# STM32G431C6T6 register map
File version: 1.0
Registers are 32-bit, access not given, reset 0x0 unless marked. A register's access mark holds for its fields unless they carry their own. Offsets are from the block's base; [hi:lo] are bit positions; {n}, {i} and the like mark numbered series; 'fields as' and 'values as' point back to an identical list.

## HRTIM
Base 0x40016800
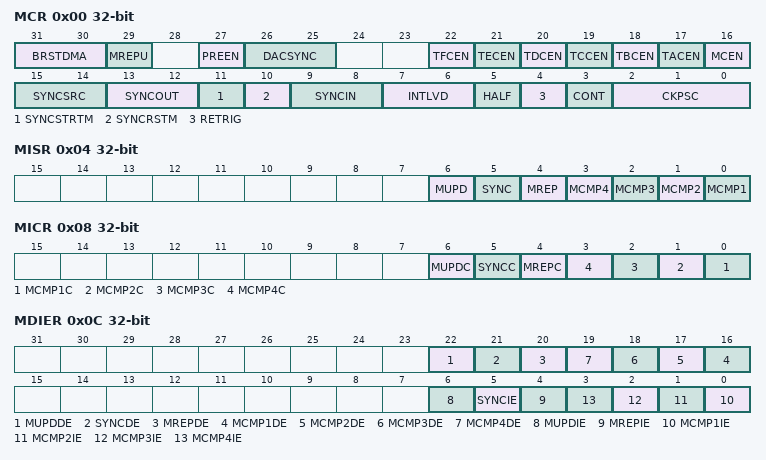
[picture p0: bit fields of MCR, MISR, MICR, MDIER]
0x00 MCR
  [31:30] BRSTDMA, [29] MREPU, [27] PREEN, [26:25] DACSYNC, [22] TFCEN, [21] TECEN, [20] TDCEN, [19] TCCEN, [18] TBCEN, [17] TACEN, [16] MCEN, [15:14] SYNCSRC, [13:12] SYNCOUT, [11] SYNCSTRTM, [10] SYNCRSTM, [9:8] SYNCIN, [7:6] INTLVD, [5] HALF, [4] RETRIG, [3] CONT, [2:0] CKPSC
0x04 MISR
  [6] MUPD, [5] SYNC, [4] MREP, [n-1] MCMP{n} (n=1..4)
0x08 MICR
  [6] MUPDC, [5] SYNCC, [4] MREPC, [n-1] MCMP{n}C (n=1..4)
0x0C MDIER
  [22] MUPDDE, [21] SYNCDE, [20] MREPDE, [n+15] MCMP{n}DE (n=1..4), [6] MUPDIE, [5] SYNCIE, [4] MREPIE, [n-1] MCMP{n}IE (n=1..4)
0x10 MCNTR
  [15:0] MCNT
0x14 MPER
  [15:0] MPER
0x18 MREP
  [7:0] MREP
0x1C MCMP1R
  [15:0] MCMP1
{0x1C+4i} MCMP{i}R (i=2..4)
  [15:0] MCMP{i}
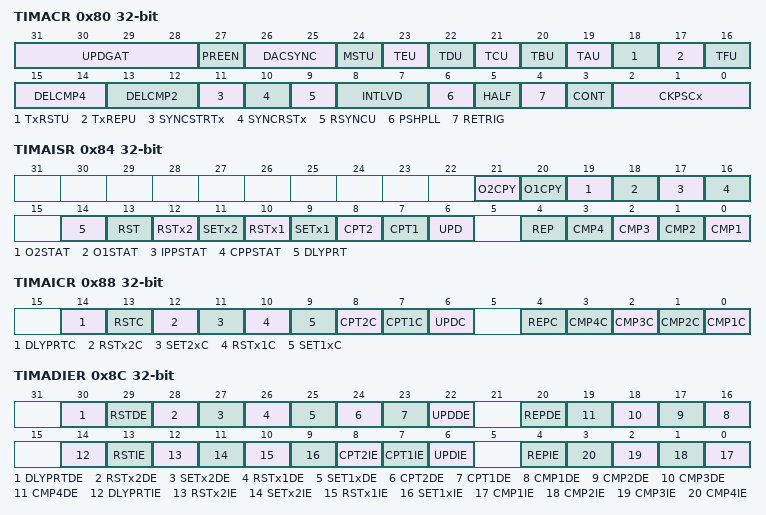
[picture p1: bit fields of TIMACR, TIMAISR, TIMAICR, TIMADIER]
0x80 TIMACR
  [31:28] UPDGAT, [27] PREEN, [26:25] DACSYNC, [24] MSTU, [23] TEU, [22] TDU, [21] TCU, [20] TBU, [19] TAU, [18] TxRSTU, [17] TxREPU, [16] TFU, [15:14] DELCMP4, [13:12] DELCMP2, [11] SYNCSTRTx, [10] SYNCRSTx, [9] RSYNCU, [8:7] INTLVD, [6] PSHPLL, [5] HALF, [4] RETRIG, [3] CONT, [2:0] CKPSCx
0x84 TIMAISR
  [21] O2CPY, [20] O1CPY, [19] O2STAT, [18] O1STAT, [17] IPPSTAT, [16] CPPSTAT, [14] DLYPRT, [13] RST, [12] RSTx2, [11] SETx2, [10] RSTx1, [9] SETx1, [8] CPT2, [7] CPT1, [6] UPD, [4] REP, [n-1] CMP{n} (n=1..4)
0x88 TIMAICR
  [14] DLYPRTC, [13] RSTC, [12] RSTx2C, [11] SET2xC, [10] RSTx1C, [9] SET1xC, [8] CPT2C, [7] CPT1C, [6] UPDC, [4] REPC, [n-1] CMP{n}C (n=1..4)
0x8C TIMADIER
  [30] DLYPRTDE, [29] RSTDE, [28] RSTx2DE, [27] SETx2DE, [26] RSTx1DE, [25] SET1xDE, [24] CPT2DE, [23] CPT1DE, [22] UPDDE, [20] REPDE, [n+15] CMP{n}DE (n=1..4), [14] DLYPRTIE, [13] RSTIE, [12] RSTx2IE, [11] SETx2IE, [10] RSTx1IE, [9] SET1xIE, [8] CPT2IE, [7] CPT1IE, [6] UPDIE, [4] REPIE, [n-1] CMP{n}IE (n=1..4)
0x90 CNTAR
  [15:0] CNTx
0x94 PERAR
  [15:0] PERx
0x98 REPAR
  [7:0] REPx
0x9C CMP1AR
  [15:0] CMP1x
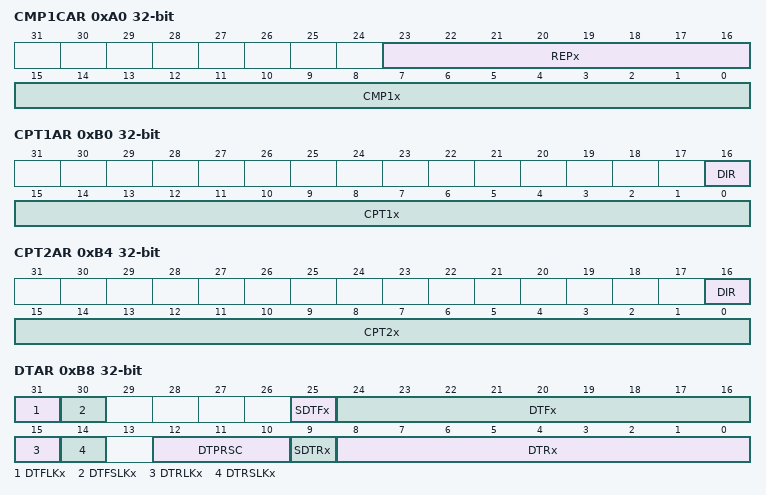
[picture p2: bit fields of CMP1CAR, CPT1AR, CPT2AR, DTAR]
0xA0 CMP1CAR
  [23:16] REPx, [15:0] CMP1x
{0x9C+4i} CMP{i}AR (i=2..4)
  [15:0] CMP{i}x
0xB0 CPT1AR
  [16] DIR, [15:0] CPT1x
0xB4 CPT2AR
  [16] DIR, [15:0] CPT2x
0xB8 DTAR
  [31] DTFLKx, [30] DTFSLKx, [25] SDTFx, [24:16] DTFx, [15] DTRLKx, [14] DTRSLKx, [12:10] DTPRSC, [9] SDTRx, [8:0] DTRx
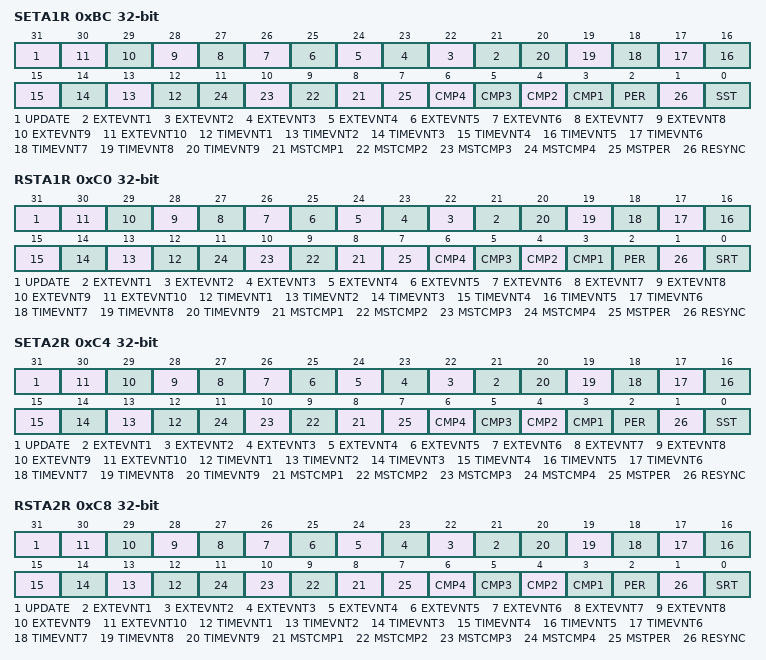
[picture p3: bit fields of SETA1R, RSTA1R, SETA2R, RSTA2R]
0xBC SETA1R
  [31] UPDATE, [n+20] EXTEVNT{n} (n=1..10), [n+11] TIMEVNT{n} (n=1..9), [n+7] MSTCMP{n} (n=1..4), [7] MSTPER, [n+2] CMP{n} (n=1..4), [2] PER, [1] RESYNC, [0] SST
0xC0 RSTA1R
  [31] UPDATE, [n+20] EXTEVNT{n} (n=1..10), [n+11] TIMEVNT{n} (n=1..9), [n+7] MSTCMP{n} (n=1..4), [7] MSTPER, [n+2] CMP{n} (n=1..4), [2] PER, [1] RESYNC, [0] SRT
0xC4 SETA2R
  fields as SETA1R
0xC8 RSTA2R
  fields as RSTA1R
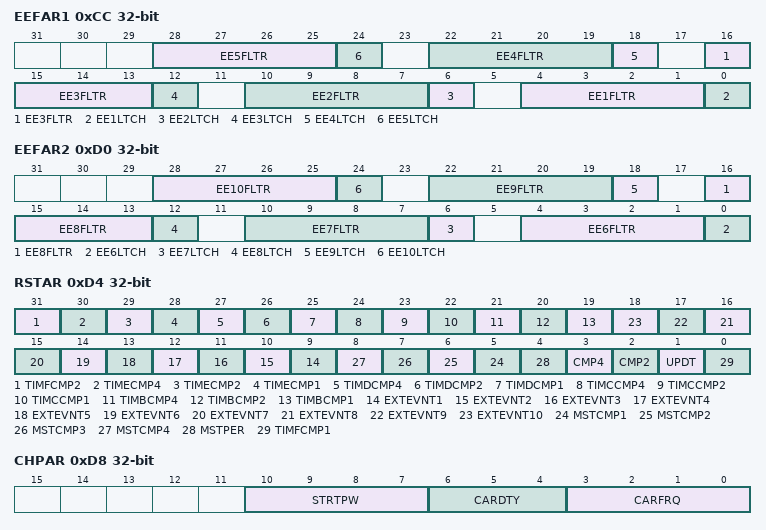
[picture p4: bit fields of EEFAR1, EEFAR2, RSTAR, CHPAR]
0xCC EEFAR1
  [6n-2:6n-5] EE{n}FLTR (n=1..5), [6n-6] EE{n}LTCH (n=1..5)
0xD0 EEFAR2
  [6n-32:6n-35] EE{n}FLTR (n=6..10), [6n-36] EE{n}LTCH (n=6..10)
0xD4 RSTAR
  [31] TIMFCMP2, [30] TIMECMP4, [29] TIMECMP2, [28] TIMECMP1, [27] TIMDCMP4, [26] TIMDCMP2, [25] TIMDCMP1, [24] TIMCCMP4, [23] TIMCCMP2, [22] TIMCCMP1, [21] TIMBCMP4, [20] TIMBCMP2, [19] TIMBCMP1, [n+8] EXTEVNT{n} (n=1..10), [n+4] MSTCMP{n} (n=1..4), [4] MSTPER, [3] CMP4, [2] CMP2, [1] UPDT, [0] TIMFCMP1
0xD8 CHPAR
  [10:7] STRTPW, [6:4] CARDTY, [3:0] CARFRQ
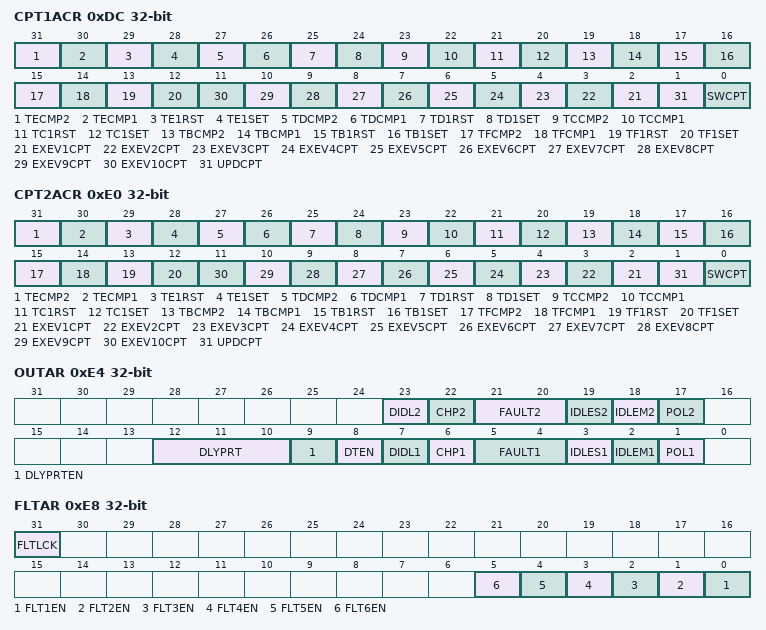
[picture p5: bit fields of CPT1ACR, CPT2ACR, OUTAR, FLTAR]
0xDC CPT1ACR
  [31] TECMP2, [30] TECMP1, [29] TE1RST, [28] TE1SET, [27] TDCMP2, [26] TDCMP1, [25] TD1RST, [24] TD1SET, [23] TCCMP2, [22] TCCMP1, [21] TC1RST, [20] TC1SET, [19] TBCMP2, [18] TBCMP1, [17] TB1RST, [16] TB1SET, [15] TFCMP2, [14] TFCMP1, [13] TF1RST, [12] TF1SET, [n+1] EXEV{n}CPT (n=1..10), [1] UPDCPT, [0] SWCPT
0xE0 CPT2ACR
  fields as CPT1ACR
0xE4 OUTAR
  [23] DIDL2, [22] CHP2, [21:20] FAULT2, [19] IDLES2, [18] IDLEM2, [17] POL2, [12:10] DLYPRT, [9] DLYPRTEN, [8] DTEN, [7] DIDL1, [6] CHP1, [5:4] FAULT1, [3] IDLES1, [2] IDLEM1, [1] POL1
0xE8 FLTAR
  [31] FLTLCK, [n-1] FLT{n}EN (n=1..6)
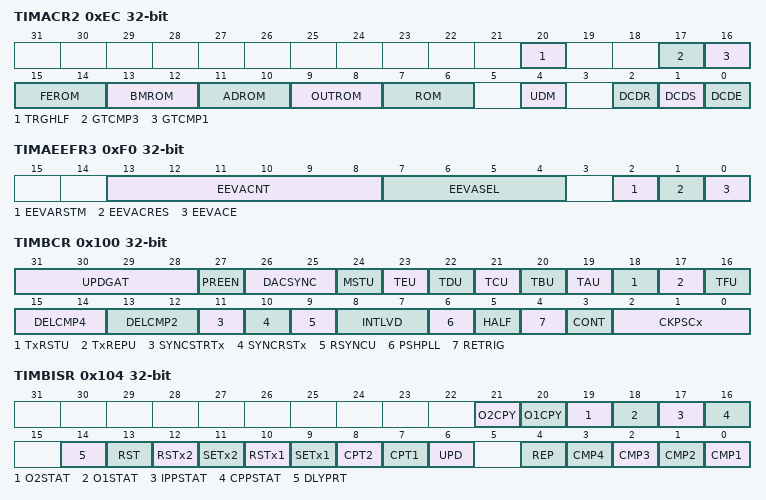
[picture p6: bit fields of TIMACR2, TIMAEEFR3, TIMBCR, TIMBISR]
0xEC TIMACR2
  [20] TRGHLF, [17] GTCMP3, [16] GTCMP1, [15:14] FEROM, [13:12] BMROM, [11:10] ADROM, [9:8] OUTROM, [7:6] ROM, [4] UDM, [2] DCDR, [1] DCDS, [0] DCDE
0xF0 TIMAEEFR3
  [13:8] EEVACNT, [7:4] EEVASEL, [2] EEVARSTM, [1] EEVACRES, [0] EEVACE
0x100 TIMBCR
  fields as TIMACR
0x104 TIMBISR
  fields as TIMAISR
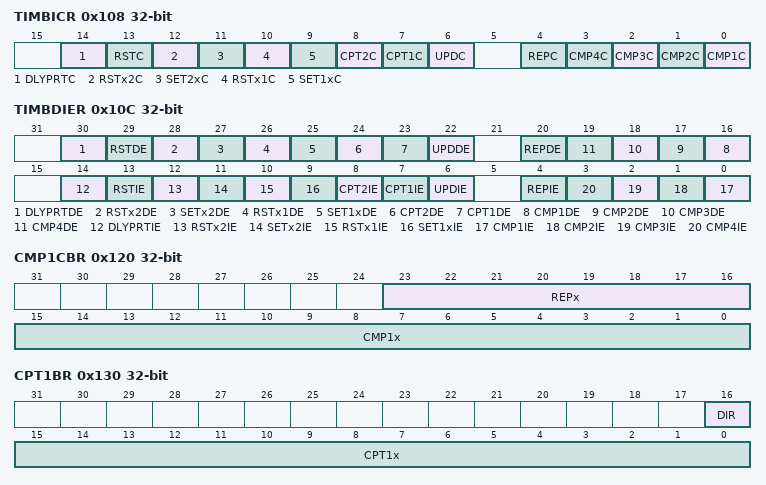
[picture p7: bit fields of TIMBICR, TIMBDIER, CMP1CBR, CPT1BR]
0x108 TIMBICR
  fields as TIMAICR
0x10C TIMBDIER
  fields as TIMADIER
0x110 CNTBR
  [15:0] CNTx
0x114 PERBR
  [15:0] PERx
0x118 REPBR
  [7:0] REPx
0x11C CMP1BR
  [15:0] CMP1x
0x120 CMP1CBR
  [23:16] REPx, [15:0] CMP1x
{0x11C+4i} CMP{i}BR (i=2..4)
  [15:0] CMP{i}x
0x130 CPT1BR
  [16] DIR, [15:0] CPT1x
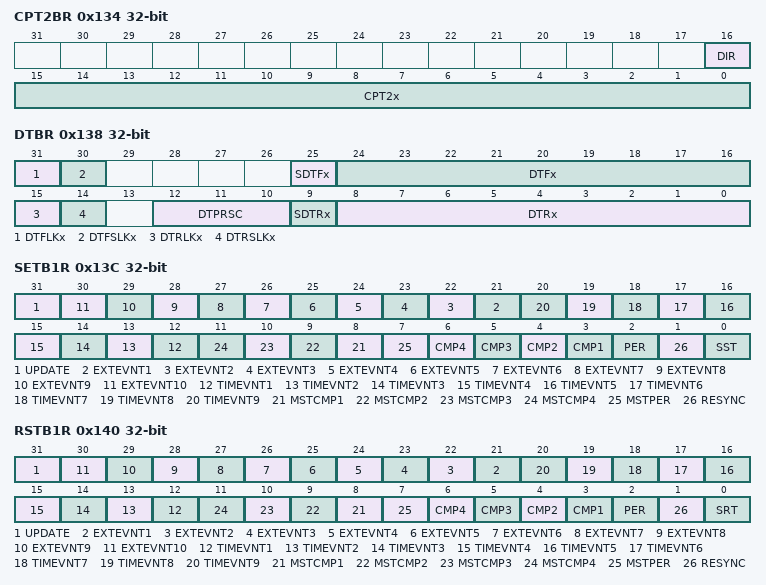
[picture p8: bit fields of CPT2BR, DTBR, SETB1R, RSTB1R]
0x134 CPT2BR
  [16] DIR, [15:0] CPT2x
0x138 DTBR
  fields as DTAR
0x13C SETB1R
  fields as SETA1R
0x140 RSTB1R
  fields as RSTA1R
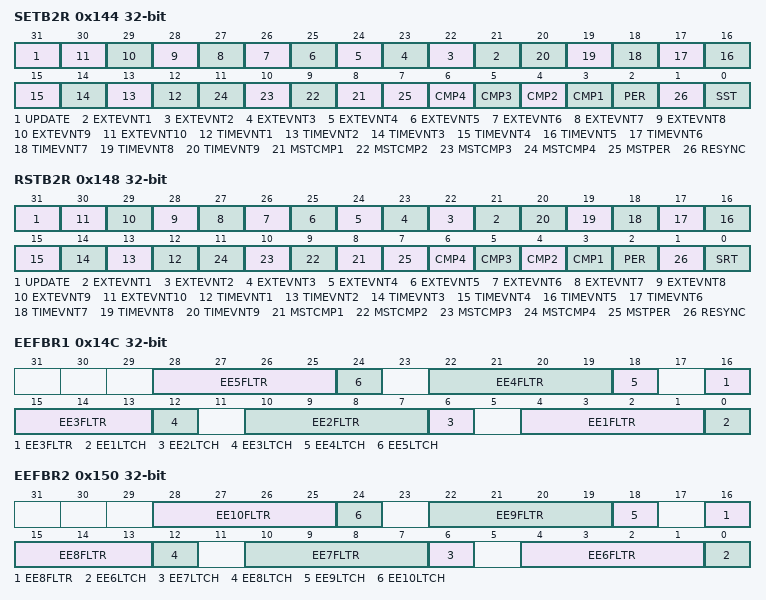
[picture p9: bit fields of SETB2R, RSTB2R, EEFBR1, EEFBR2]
0x144 SETB2R
  fields as SETA1R
0x148 RSTB2R
  fields as RSTA1R
0x14C EEFBR1
  [6n-2:6n-5] EE{n}FLTR (n=1..5), [6n-6] EE{n}LTCH (n=1..5)
0x150 EEFBR2
  [6n-32:6n-35] EE{n}FLTR (n=6..10), [6n-36] EE{n}LTCH (n=6..10)
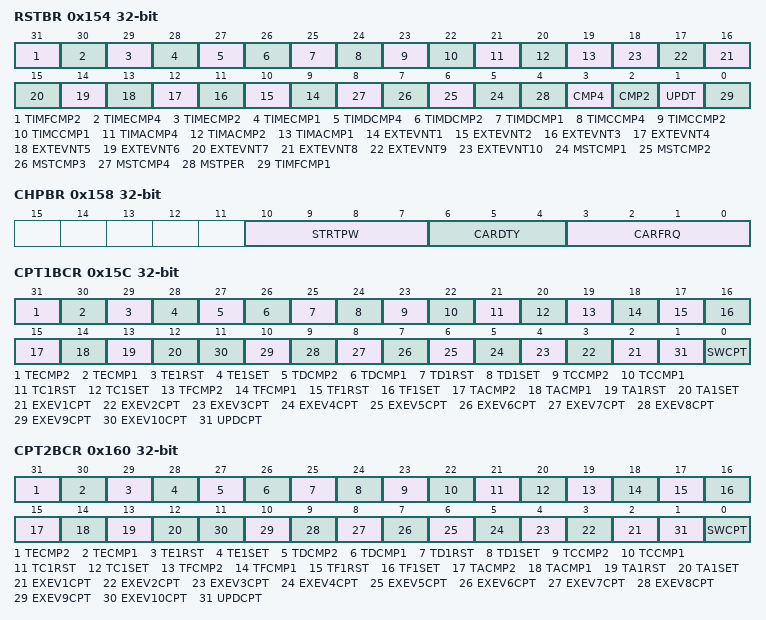
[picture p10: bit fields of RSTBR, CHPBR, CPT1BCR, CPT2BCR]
0x154 RSTBR
  [31] TIMFCMP2, [30] TIMECMP4, [29] TIMECMP2, [28] TIMECMP1, [27] TIMDCMP4, [26] TIMDCMP2, [25] TIMDCMP1, [24] TIMCCMP4, [23] TIMCCMP2, [22] TIMCCMP1, [21] TIMACMP4, [20] TIMACMP2, [19] TIMACMP1, [n+8] EXTEVNT{n} (n=1..10), [n+4] MSTCMP{n} (n=1..4), [4] MSTPER, [3] CMP4, [2] CMP2, [1] UPDT, [0] TIMFCMP1
0x158 CHPBR
  [10:7] STRTPW, [6:4] CARDTY, [3:0] CARFRQ
0x15C CPT1BCR
  [31] TECMP2, [30] TECMP1, [29] TE1RST, [28] TE1SET, [27] TDCMP2, [26] TDCMP1, [25] TD1RST, [24] TD1SET, [23] TCCMP2, [22] TCCMP1, [21] TC1RST, [20] TC1SET, [19] TFCMP2, [18] TFCMP1, [17] TF1RST, [16] TF1SET, [15] TACMP2, [14] TACMP1, [13] TA1RST, [12] TA1SET, [n+1] EXEV{n}CPT (n=1..10), [1] UPDCPT, [0] SWCPT
0x160 CPT2BCR
  fields as CPT1BCR
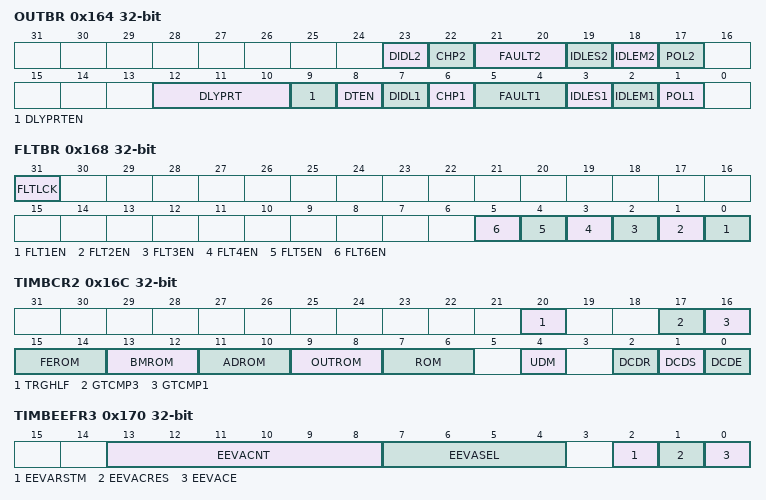
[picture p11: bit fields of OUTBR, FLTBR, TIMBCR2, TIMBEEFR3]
0x164 OUTBR
  fields as OUTAR
0x168 FLTBR
  [31] FLTLCK, [n-1] FLT{n}EN (n=1..6)
0x16C TIMBCR2
  fields as TIMACR2
0x170 TIMBEEFR3
  fields as TIMAEEFR3
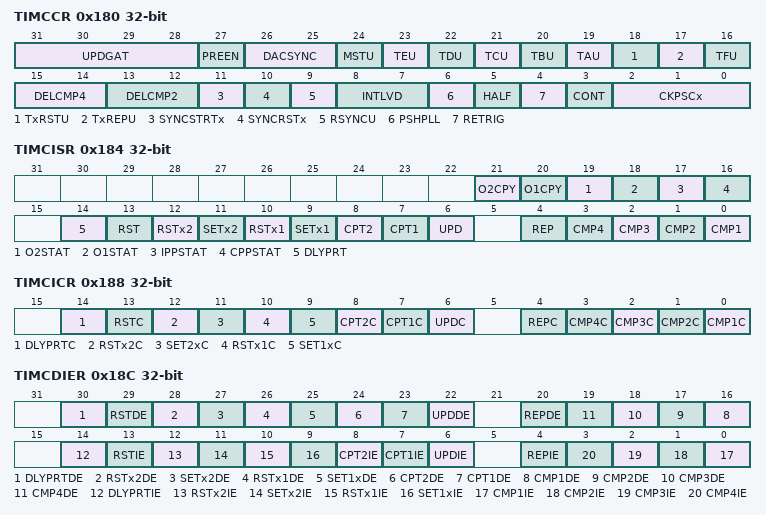
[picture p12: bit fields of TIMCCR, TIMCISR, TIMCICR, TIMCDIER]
0x180 TIMCCR
  fields as TIMACR
0x184 TIMCISR
  fields as TIMAISR
0x188 TIMCICR
  fields as TIMAICR
0x18C TIMCDIER
  fields as TIMADIER
0x190 CNTCR
  [15:0] CNTx
0x194 PERCR
  [15:0] PERx
0x198 REPCR
  [7:0] REPx
0x19C CMP1CR
  [15:0] CMP1x
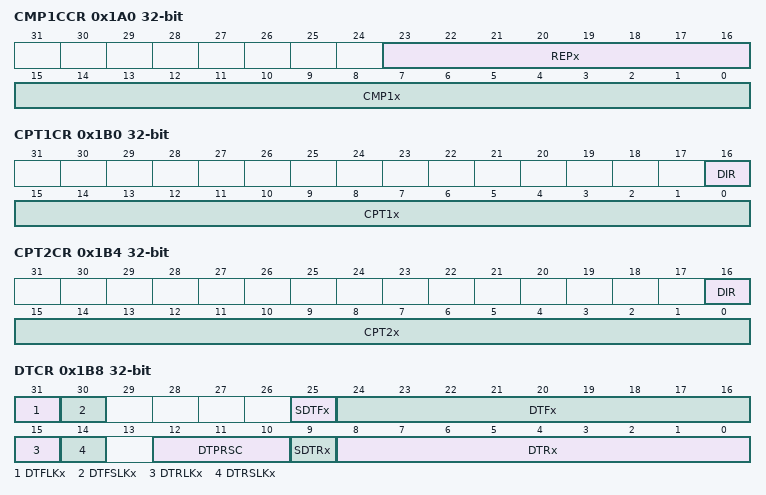
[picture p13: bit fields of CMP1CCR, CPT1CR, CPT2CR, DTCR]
0x1A0 CMP1CCR
  [23:16] REPx, [15:0] CMP1x
{0x19C+4i} CMP{i}CR (i=2..4)
  [15:0] CMP{i}x
0x1B0 CPT1CR
  [16] DIR, [15:0] CPT1x
0x1B4 CPT2CR
  [16] DIR, [15:0] CPT2x
0x1B8 DTCR
  fields as DTAR
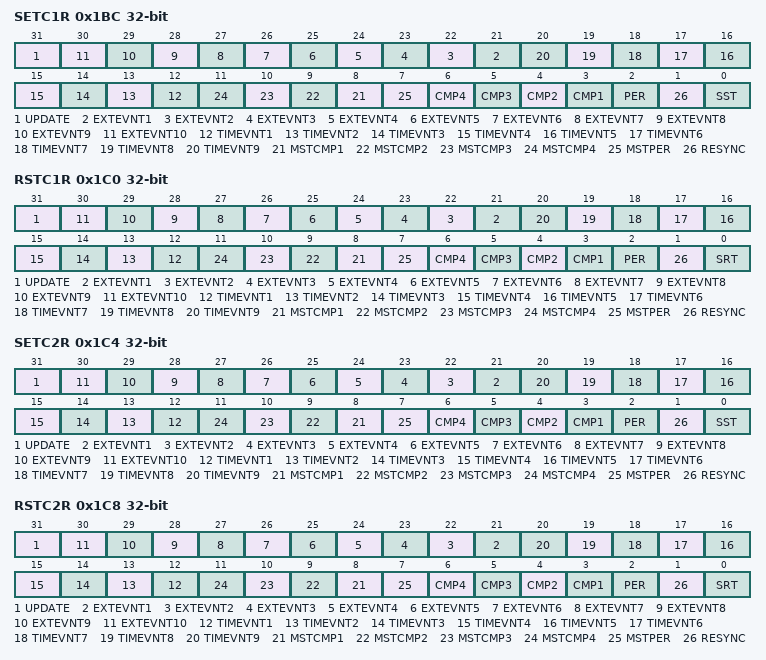
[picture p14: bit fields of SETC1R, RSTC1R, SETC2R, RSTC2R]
0x1BC SETC1R
  fields as SETA1R
0x1C0 RSTC1R
  fields as RSTA1R
0x1C4 SETC2R
  fields as SETA1R
0x1C8 RSTC2R
  fields as RSTA1R
0x1CC EEFCR1
  [6n-2:6n-5] EE{n}FLTR (n=1..5), [6n-6] EE{n}LTCH (n=1..5)
0x1D0 EEFCR2
  [6n-32:6n-35] EE{n}FLTR (n=6..10), [6n-36] EE{n}LTCH (n=6..10)
0x1D4 RSTCR
  [31] TIMFCMP2, [30] TIMECMP4, [29] TIMECMP2, [28] TIMECMP1, [27] TIMDCMP4, [26] TIMDCMP2, [25] TIMDCMP1, [24] TIMBCMP4, [23] TIMBCMP2, [22] TIMBCMP1, [21] TIMACMP4, [20] TIMACMP2, [19] TIMACMP1, [n+8] EXTEVNT{n} (n=1..10), [n+4] MSTCMP{n} (n=1..4), [4] MSTPER, [3] CMP4, [2] CMP2, [1] UPDT, [0] TIMFCMP1
0x1D8 CHPCR
  [10:7] STRTPW, [6:4] CARDTY, [3:0] CARFRQ
0x1DC CPT1CCR
  [31] TECMP2, [30] TECMP1, [29] TE1RST, [28] TE1SET, [27] TDCMP2, [26] TDCMP1, [25] TD1RST, [24] TD1SET, [23] TFCMP2, [22] TFCMP1, [21] TF1RST, [20] TF1SET, [19] TBCMP2, [18] TBCMP1, [17] TB1RST, [16] TB1SET, [15] TACMP2, [14] TACMP1, [13] TA1RST, [12] TA1SET, [n+1] EXEV{n}CPT (n=1..10), [1] UPDCPT, [0] SWCPT
0x1E0 CPT2CCR
  fields as CPT1CCR
0x1E4 OUTCR
  fields as OUTAR
0x1E8 FLTCR
  [31] FLTLCK, [n-1] FLT{n}EN (n=1..6)
0x1EC TIMCCR2
  fields as TIMACR2
0x1F0 TIMCEEFR3
  fields as TIMAEEFR3
0x200 TIMDCR
  fields as TIMACR
0x204 TIMDISR
  fields as TIMAISR
0x208 TIMDICR
  fields as TIMAICR
0x20C TIMDDIER
  fields as TIMADIER
0x210 CNTDR
  [15:0] CNTx
0x214 PERDR
  [15:0] PERx
0x218 REPDR
  [7:0] REPx
0x21C CMP1DR
  [15:0] CMP1x
0x220 CMP1CDR
  [23:16] REPx, [15:0] CMP1x
{0x21C+4i} CMP{i}DR (i=2..4)
  [15:0] CMP{i}x
0x230 CPT1DR
  [16] DIR, [15:0] CPT1x
0x234 CPT2DR
  [16] DIR, [15:0] CPT2x
0x238 DTDR
  fields as DTAR
0x23C SETD1R
  fields as SETA1R
0x240 RSTD1R
  fields as RSTA1R
0x244 SETD2R
  fields as SETA1R
0x248 RSTD2R
  fields as RSTA1R
0x24C EEFDR1
  [6n-2:6n-5] EE{n}FLTR (n=1..5), [6n-6] EE{n}LTCH (n=1..5)
0x250 EEFDR2
  [6n-32:6n-35] EE{n}FLTR (n=6..10), [6n-36] EE{n}LTCH (n=6..10)
0x254 RSTDR
  [31] TIMFCMP2, [30] TIMECMP4, [29] TIMECMP2, [28] TIMECMP1, [27] TIMCCMP4, [26] TIMCCMP2, [25] TIMCCMP1, [24] TIMBCMP4, [23] TIMBCMP2, [22] TIMBCMP1, [21] TIMACMP4, [20] TIMACMP2, [19] TIMACMP1, [n+8] EXTEVNT{n} (n=1..10), [n+4] MSTCMP{n} (n=1..4), [4] MSTPER, [3] CMP4, [2] CMP2, [1] UPDT, [0] TIMFCMP1
0x258 CHPDR
  [10:7] STRTPW, [6:4] CARDTY, [3:0] CARFRQ
0x25C CPT1DCR
  [31] TECMP2, [30] TECMP1, [29] TE1RST, [28] TE1SET, [27] TFCMP2, [26] TFCMP1, [25] TF1RST, [24] TF1SET, [23] TCCMP2, [22] TCCMP1, [21] TC1RST, [20] TC1SET, [19] TBCMP2, [18] TBCMP1, [17] TB1RST, [16] TB1SET, [15] TACMP2, [14] TACMP1, [13] TA1RST, [12] TA1SET, [n+1] EXEV{n}CPT (n=1..10), [1] UPDCPT, [0] SWCPT
0x260 CPT2DCR
  fields as CPT1DCR
0x264 OUTDR
  fields as OUTAR
0x268 FLTDR
  [31] FLTLCK, [n-1] FLT{n}EN (n=1..6)
0x26C TIMDCR2
  fields as TIMACR2
0x270 TIMDEEFR3
  fields as TIMAEEFR3
0x280 TIMECR
  fields as TIMACR
0x284 TIMEISR
  fields as TIMAISR
0x288 TIMEICR
  fields as TIMAICR
0x28C TIMEDIER
  fields as TIMADIER
0x290 CNTER
  [15:0] CNTx
0x294 PERER
  [15:0] PERx
0x298 REPER
  [7:0] REPx
0x29C CMP1ER
  [15:0] CMP1x
0x2A0 CMP1CER
  [23:16] REPx, [15:0] CMP1x
{0x29C+4i} CMP{i}ER (i=2..4)
  [15:0] CMP{i}x
0x2B0 CPT1ER
  [16] DIR, [15:0] CPT1x
0x2B4 CPT2ER
  [16] DIR, [15:0] CPT2x
0x2B8 DTER
  fields as DTAR
0x2BC SETE1R
  fields as SETA1R
0x2C0 RSTE1R
  fields as RSTA1R
0x2C4 SETE2R
  fields as SETA1R
0x2C8 RSTE2R
  fields as RSTA1R
0x2CC EEFER1
  [6n-2:6n-5] EE{n}FLTR (n=1..5), [6n-6] EE{n}LTCH (n=1..5)
0x2D0 EEFER2
  [6n-32:6n-35] EE{n}FLTR (n=6..10), [6n-36] EE{n}LTCH (n=6..10)
0x2D4 RSTER
  [31] TIMFCMP2, [30] TIMDCMP4, [29] TIMDCMP2, [28] TIMDCMP1, [27] TIMCCMP4, [26] TIMCCMP2, [25] TIMCCMP1, [24] TIMBCMP4, [23] TIMBCMP2, [22] TIMBCMP1, [21] TIMACMP4, [20] TIMACMP2, [19] TIMACMP1, [n+8] EXTEVNT{n} (n=1..10), [n+4] MSTCMP{n} (n=1..4), [4] MSTPER, [3] CMP4, [2] CMP2, [1] UPDT, [0] TIMFCMP1
0x2D8 CHPER
  [10:7] STRTPW, [6:4] CARDTY, [3:0] CARFRQ
0x2DC CPT1ECR
  [31] TFCMP2, [30] TFCMP1, [29] TF1RST, [28] TF1SET, [27] TDCMP2, [26] TDCMP1, [25] TD1RST, [24] TD1SET, [23] TCCMP2, [22] TCCMP1, [21] TC1RST, [20] TC1SET, [19] TBCMP2, [18] TBCMP1, [17] TB1RST, [16] TB1SET, [15] TACMP2, [14] TACMP1, [13] TA1RST, [12] TA1SET, [n+1] EXEV{n}CPT (n=1..10), [1] UPDCPT, [0] SWCPT
0x2E0 CPT2ECR
  fields as CPT1ECR
0x2E4 OUTER
  fields as OUTAR
0x2E8 FLTER
  [31] FLTLCK, [n-1] FLT{n}EN (n=1..6)
0x2EC TIMECR2
  fields as TIMACR2
0x2F0 TIMEEEFR3
  fields as TIMAEEFR3
0x300 TIMFCR
  fields as TIMACR
0x304 TIMFISR
  fields as TIMAISR
0x308 TIMFICR
  fields as TIMAICR
0x30C TIMFDIER
  fields as TIMADIER
0x310 CNTFR
  [15:0] CNTx
0x314 PERFR
  [15:0] PERx
0x318 REPFR
  [7:0] REPx
0x31C CMP1FR
  [15:0] CMP1x
0x320 CMP1CFR
  [23:16] REPx, [15:0] CMP1x
{0x31C+4i} CMP{i}FR (i=2..4)
  [15:0] CMP{i}x
0x330 CPT1FR
  [16] DIR, [15:0] CPT1x
0x334 CPT2FR
  [16] DIR, [15:0] CPT2x
0x338 DTFR
  fields as DTAR
0x33C SETF1R
  fields as SETA1R
0x340 RSTF1R
  fields as RSTA1R
0x344 SETF2R
  fields as SETA1R
0x348 RSTF2R
  fields as RSTA1R
0x34C EEFFR1
  [6n-2:6n-5] EE{n}FLTR (n=1..5), [6n-6] EE{n}LTCH (n=1..5)
0x350 EEFFR2
  [6n-32:6n-35] EE{n}FLTR (n=6..10), [6n-36] EE{n}LTCH (n=6..10)
0x354 RSTFR
  [31] TIMECMP2, [30] TIMDCMP4, [29] TIMDCMP2, [28] TIMDCMP1, [27] TIMCCMP4, [26] TIMCCMP2, [25] TIMCCMP1, [24] TIMBCMP4, [23] TIMBCMP2, [22] TIMBCMP1, [21] TIMACMP4, [20] TIMACMP2, [19] TIMACMP1, [n+8] EXTEVNT{n} (n=1..10), [n+4] MSTCMP{n} (n=1..4), [4] MSTPER, [3] CMP4, [2] CMP2, [1] UPDT, [0] TIMECMP1
0x358 CHPFR
  [10:7] STRTPW, [6:4] CARDTY, [3:0] CARFRQ
0x35C CPT1FCR
  [31] TECMP2, [30] TECMP1, [29] TE1RST, [28] TE1SET, [27] TDCMP2, [26] TDCMP1, [25] TD1RST, [24] TD1SET, [23] TCCMP2, [22] TCCMP1, [21] TC1RST, [20] TC1SET, [19] TBCMP2, [18] TBCMP1, [17] TB1RST, [16] TB1SET, [15] TACMP2, [14] TACMP1, [13] TA1RST, [12] TA1SET, [n+1] EXEV{n}CPT (n=1..10), [1] UPDCPT, [0] SWCPT
0x360 CPT2FCR
  fields as CPT1FCR
0x364 OUTFR
  fields as OUTAR
0x368 FLTFR
  [31] FLTLCK, [n-1] FLT{n}EN (n=1..6)
0x36C TIMFCR2
  fields as TIMACR2
0x370 TIMFEEFR3
  fields as TIMAEEFR3
0x380 CR1
  [3n+15:3n+13] AD{n}USRC (n=1..4), [6] TFUDIS, [5] TEUDIS, [4] TDUDIS, [3] TCUDIS, [2] TBUDIS, [1] TAUDIS, [0] MUDIS
0x384 CR2
  [21] SWPF, [20] SWPE, [19] SWPD, [18] SWPC, [17] SWPB, [16] SWPA, [14] TFRST, [13] TERST, [12] TDRST, [11] TCRST, [10] TBRST, [9] TARST, [8] MRST, [6] TFSWU, [5] TESWU, [4] TDSWU, [3] TCSWU, [2] TBSWU, [1] TASWU, [0] MSWU
0x388 ISR
  [17] BMPER, [16] DLLRDY, [6] FLT6, [5] SYSFLT, [n-1] FLT{n} (n=1..5)
0x38C ICR
  [17] BMPERC, [16] DLLRDYC, [6] FLT6C, [5] SYSFLTC, [n-1] FLT{n}C (n=1..5)
0x390 IER
  [17] BMPERIE, [16] DLLRDYIE, [6] FLT6IE, [5] SYSFLTIE, [n-1] FLT{n}IE (n=1..5)
0x394 OENR
  [11] TF2OEN, [10] TF1OEN, [9] TE2OEN, [8] TE1OEN, [7] TD2OEN, [6] TD1OEN, [5] TC2OEN, [4] TC1OEN, [3] TB2OEN, [2] TB1OEN, [1] TA2OEN, [0] TA1OEN
0x398 ODISR
  [11] TF2ODIS, [10] TF1ODIS, [9] TE2ODIS, [8] TE1ODIS, [7] TD2ODIS, [6] TD1ODIS, [5] TC2ODIS, [4] TC1ODIS, [3] TB2ODIS, [2] TB1ODIS, [1] TA2ODIS, [0] TA1ODIS
0x39C ODSR
  [11] TF2ODS, [10] TF1ODS, [9] TE2ODS, [8] TE1ODS, [7] TD2ODS, [6] TD1ODS, [5] TC2ODS, [4] TC1ODS, [3] TB2ODS, [2] TB1ODS, [1] TA2ODS, [0] TA1ODS
0x3A0 BMCR
  [31] BMSTAT, [22] TFBM, [21] TEBM, [20] TDBM, [19] TCBM, [18] TBBM, [17] TABM, [16] MTBM, [10] BMPREN, [9:6] BMPRSC, [5:2] BMCLK, [1] BMOM, [0] BME
0x3A4 BMTRG
  [31] OCHPEV, [30] EEV8, [29] EEV7, [28] TDEEV8, [27] TAEEV7, [26] TECMP2, [25] TECMP1, [24] TEREP, [23] TFCMP1, [22] TDCMP2, [21] TFREP, [20] TDREP, [19] TDRST, [18] TFRST, [17] TCCMP1, [16] TCREP, [15] TCRST, [14] TBCMP2, [13] TBCMP1, [12] TBREP, [11] TBRST, [10] TACMP2, [9] TACMP1, [8] TAREP, [7] TARST, [n+2] MSTCMP{n} (n=1..4), [2] MSTREP, [1] MSTRST, [0] SW
0x3A8 BMCMPR
  [15:0] BMCMP
0x3AC BMPER
  [15:0] BMPER
0x3B0 EECR1
  [6n-1] EE{n}FAST (n=1..5), [6n-2:6n-3] EE{n}SNS (n=1..5), [6n-4] EE{n}POL (n=1..5), [6n-5:6n-6] EE{n}SRC (n=1..5)
0x3B4 EECR2
  [6n-32:6n-33] EE{n}SNS (n=6..10), [6n-34] EE{n}POL (n=6..10), [6n-35:6n-36] EE{n}SRC (n=6..10)
0x3B8 EECR3
  [31:30] EEVSD, [6n-33:6n-36] EE{n}F (n=6..10)
0x3BC ADC1R
  [31] ADC1TEPER, [30] ADC1TEC4, [29] ADC1TEC3, [28] ADC1TFRST, [27] ADC1TDPER, [26] ADC1TDC4, [25] ADC1TDC3, [24] ADC1TFPER, [23] ADC1TCPER, [22] ADC1TCC4, [21] ADC1TCC3, [20] ADC1TFC4, [19] ADC1TBRST, [18] ADC1TBPER, [17] ADC1TBC4, [16] ADC1TBC3, [15] ADC1TFC3, [14] ADC1TARST, [13] ADC1TAPER, [12] ADC1TAC4, [11] ADC1TAC3, [10] ADC1TFC2, [n+4] ADC1EEV{n} (n=1..5), [4] ADC1MPER, [n-1] ADC1MC{n} (n=1..4)
0x3C0 ADC2R
  [31] ADC2TERST, [30] ADC2TEC4, [29] ADC2TEC3, [28] ADC2TEC2, [27] ADC2TDRST, [26] ADC2TDPER, [25] ADC2TDC4, [24] ADC2TFPER, [23] ADC2TDC2, [22] ADC2TCRST, [21] ADC2TCPER, [20] ADC2TCC4, [19] ADC2TFC4, [18] ADC2TCC2, [17] ADC2TBPER, [16] ADC2TBC4, [15] ADC2TFC3, [14] ADC2TBC2, [13] ADC2TAPER, [12] ADC2TAC4, [11] ADC2TFC2, [10] ADC2TAC2, [n-1] ADC2EEV{n} (n=6..10), [4] ADC2MPER, [n-1] ADC2MC{n} (n=1..4)
0x3C4 ADC3R
  [31] ADC3TEPER, [30] ADC3TEC4, [29] ADC3TEC3, [28] ADC3TFRST, [27] ADC3TDPER, [26] ADC3TDC4, [25] ADC3TDC3, [24] ADC3TFPER, [23] ADC3TCPER, [22] ADC3TCC4, [21] ADC3TCC3, [20] ADC3TFC4, [19] ADC3TBRST, [18] ADC3TBPER, [17] ADC3TBC4, [16] ADC3TBC3, [15] ADC3TFC3, [14] ADC3TARST, [13] ADC3TAPER, [12] ADC3TAC4, [11] ADC3TAC3, [10] ADC3TFC2, [n+4] ADC3EEV{n} (n=1..5), [4] ADC3MPER, [n-1] ADC3MC{n} (n=1..4)
0x3C8 ADC4R
  [31] ADC4TERST, [30] ADC4TEC4, [29] ADC4TEC3, [28] ADC4TEC2, [27] ADC4TDRST, [26] ADC4TDPER, [25] ADC4TDC4, [24] ADC4TFPER, [23] ADC4TDC2, [22] ADC4TCRST, [21] ADC4TCPER, [20] ADC4TCC4, [19] ADC4TFC4, [18] ADC4TCC2, [17] ADC4TBPER, [16] ADC4TBC4, [15] ADC4TFC3, [14] ADC4TBC2, [13] ADC4TAPER, [12] ADC4TAC4, [11] ADC4TFC2, [10] ADC4TAC2, [n-1] ADC4EEV{n} (n=6..10), [4] ADC4MPER, [n-1] ADC4MC{n} (n=1..4)
0x3CC DLLCR
  [3:2] CALRTE, [1] CALEN, [0] CAL
0x3D0 FLTINR1
  [8n-1] FLT{n}LCK (n=1..4), [8n-2:8n-5] FLT{n}F (n=1..4), [8n-6] FLT{n}SRC (n=1..4), [8n-7] FLT{n}P (n=1..4), [8n-8] FLT{n}E (n=1..4)
0x3D4 FLTINR2
  [25:24] FLTSD, [n+15] FLT{n}SRC (n=1..4), [15] FLT6LCK, [14:11] FLT6F, [21:10] FLT6SRC, [9] FLT6P, [8] FLT6E, [7] FLT5LCK, [6:3] FLT5F, [20:2] FLT5SRC, [1] FLT5P, [0] FLT5E
0x3D8 BDMUPDR
  [n+5] MCMP{n} (n=1..4), [5] MREP, [4] MPER, [3] MCNT, [2] MDIER, [1] MICR, [0] MCR
0x3DC BDTAUPR
  [22] TIMAEEFR3, [21] TIMACR2, [20] TIMAFLTR, [19] TIMAOUTR, [18] TIMACHPR, [17] TIMARSTR, [16] TIMAEEFR2, [15] TIMAEEFR1, [14] TIMARST2R, [13] TIMASET2R, [12] TIMARST1R, [11] TIMASET1R, [10] TIMADTxR, [n+5] TIMACMP{n} (n=1..4), [5] TIMAREP, [4] TIMAPER, [3] TIMACNT, [2] TIMADIER, [1] TIMAICR, [0] TIMACR
0x3E0 BDTBUPR
  [22] TIMBEEFR3, [21] TIMBCR2, [20] TIMBFLTR, [19] TIMBOUTR, [18] TIMBCHPR, [17] TIMBRSTR, [16] TIMBEEFR2, [15] TIMBEEFR1, [14] TIMBRST2R, [13] TIMBSET2R, [12] TIMBRST1R, [11] TIMBSET1R, [10] TIMBDTxR, [n+5] TIMBCMP{n} (n=1..4), [5] TIMBREP, [4] TIMBPER, [3] TIMBCNT, [2] TIMBDIER, [1] TIMBICR, [0] TIMBCR
0x3E4 BDTCUPR
  [22] TIMCEEFR3, [21] TIMCCR2, [20] TIMCFLTR, [19] TIMCOUTR, [18] TIMCCHPR, [17] TIMCRSTR, [16] TIMCEEFR2, [15] TIMCEEFR1, [14] TIMCRST2R, [13] TIMCSET2R, [12] TIMCRST1R, [11] TIMCSET1R, [10] TIMCDTxR, [n+5] TIMCCMP{n} (n=1..4), [5] TIMCREP, [4] TIMCPER, [3] TIMCCNT, [2] TIMCDIER, [1] TIMCICR, [0] TIMCCR
0x3E8 BDTDUPR
  [22] TIMDEEFR3, [21] TIMDCR2, [20] TIMDFLTR, [19] TIMDOUTR, [18] TIMDCHPR, [17] TIMDRSTR, [16] TIMDEEFR2, [15] TIMDEEFR1, [14] TIMDRST2R, [13] TIMDSET2R, [12] TIMDRST1R, [11] TIMDSET1R, [10] TIMDDTxR, [n+5] TIMDCMP{n} (n=1..4), [5] TIMDREP, [4] TIMDPER, [3] TIMDCNT, [2] TIMDDIER, [1] TIMDICR, [0] TIMDCR
0x3EC BDTEUPR
  [22] TIMEEEFR3, [21] TIMECR2, [20] TIMEFLTR, [19] TIMEOUTR, [18] TIMECHPR, [17] TIMERSTR, [16] TIMEEEFR2, [15] TIMEEEFR1, [14] TIMERST2R, [13] TIMESET2R, [12] TIMERST1R, [11] TIMESET1R, [10] TIMEDTxR, [n+5] TIMECMP{n} (n=1..4), [5] TIMEREP, [4] TIMEPER, [3] TIMECNT, [2] TIMEDIER, [1] TIMEICR, [0] TIMECR
0x3F0 BDMADR
0x3F4 BDTFUPR
  [22] TIMFEEFR3, [21] TIMFCR2, [20] TIMFFLTR, [19] TIMFOUTR, [18] TIMFCHPR, [17] TIMFRSTR, [16] TIMFEEFR2, [15] TIMFEEFR1, [14] TIMFRST2R, [13] TIMFSET2R, [12] TIMFRST1R, [11] TIMFSET1R, [10] TIMFDTxR, [n+5] TIMFCMP{n} (n=1..4), [5] TIMFREP, [4] TIMFPER, [3] TIMFCNT, [2] TIMFDIER, [1] TIMFICR, [0] TIMFCR
0x3F8 ADCER
  [30:26] ADC10TRG, [25:21] ADC9TRG, [20:16] ADC8TRG, [14:10] ADC7TRG, [9:5] ADC6TRG, [4:0] ADC5TRG
0x3FC ADCUR
  [4n-18:4n-20] AD{n}USRC (n=5..10)
0x400 ADCPS1
  [6n-2:6n-6] ADC{n}PSC (n=1..5)
0x404 ADCPS2
  [6n-32:6n-36] ADC{n}PSC (n=6..10)
0x408 FLTINR3
  [8n-1] FLT{n}RSTM (n=1..4), [8n-2] FLT{n}CRES (n=1..4), [8n-3:8n-6] FLT{n}CNT (n=1..4), [8n-7] FLT{n}BLKS (n=1..4), [8n-8] FLT{n}BLKE (n=1..4)
0x40C FLTINR4
  [15] FLT6RSTM, [14] FLT6CRES, [13:10] FLT6CNT, [9] FLT6BLKS, [8] FLT6BLKE, [7] FLT5RSTM, [6] FLT5CRES, [5:2] FLT5CNT, [1] FLT5BLKS, [0] FLT5BLKE
